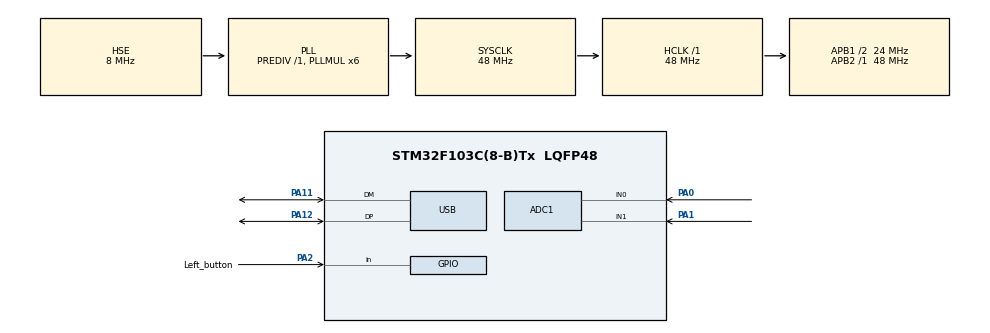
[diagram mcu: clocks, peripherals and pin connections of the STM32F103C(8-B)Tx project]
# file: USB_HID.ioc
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Mcu.Family=STM32F1
PA2.GPIO_PuPd=GPIO_PULLUP
USB_DEVICE.CLASS_NAME_FS=HID
Dma.ADC1.0.Instance=DMA1_Channel1
ADC1.Rank-0\#ChannelRegularConversion=1
PD1-OSC_OUT.Mode=HSE-External-Oscillator
ADC1.ContinuousConvMode=ENABLE
USB_DEVICE.VirtualModeFS=Hid_FS
PA11.Mode=Device
PD0-OSC_IN.Signal=RCC_OSC_IN
RCC.APB1CLKDivider=RCC_HCLK_DIV2
RCC.SYSCLKSource=RCC_SYSCLKSOURCE_PLLCLK
ProjectManager.StackSize=0x400
PA0-WKUP.Signal=ADCx_IN0
PD1-OSC_OUT.Signal=RCC_OSC_OUT
RCC.ADCPresc=RCC_ADCPCLK2_DIV4
PA13.Signal=SYS_JTMS-SWDIO
Dma.ADC1.0.PeriphDataAlignment=DMA_PDATAALIGN_HALFWORD
PA12.Signal=USB_DP
ProjectManager.TargetToolchain=MDK-ARM V5
Dma.ADC1.0.Mode=DMA_CIRCULAR
RCC.HCLKFreq_Value=48000000
Dma.ADC1.0.Priority=DMA_PRIORITY_LOW
RCC.APB2TimFreq_Value=48000000
ADC1.Channel-1\#ChannelRegularConversion=ADC_CHANNEL_1
Dma.ADC1.0.Direction=DMA_PERIPH_TO_MEMORY
RCC.USBFreq_Value=48000000
Dma.ADC1.0.MemDataAlignment=DMA_MDATAALIGN_HALFWORD
PA1.Signal=ADCx_IN1
RCC.AHBFreq_Value=48000000
PD0-OSC_IN.Mode=HSE-External-Oscillator
ADC1.Channel-0\#ChannelRegularConversion=ADC_CHANNEL_0
board=custom
RCC.PLLMUL=RCC_PLL_MUL6
VP_USB_DEVICE_VS_USB_DEVICE_HID_FS.Mode=HID_FS
RCC.APB2Freq_Value=48000000
PA14.Mode=Serial_Wire
Dma.ADC1.0.PeriphInc=DMA_PINC_DISABLE
NVIC.USB_LP_CAN1_RX0_IRQn=true\:0\:0\:false\:false\:true\:false\:true
SH.ADCx_IN0.0=ADC1_IN0,IN0
ADC1.NbrOfConversion=2
PA13.Mode=Serial_Wire
Mcu.Name=STM32F103C(8-B)Tx
ADC1.SamplingTime-0\#ChannelRegularConversion=ADC_SAMPLETIME_239CYCLES_5
PA2.Signal=GPIO_Input
ADC1.SamplingTime-1\#ChannelRegularConversion=ADC_SAMPLETIME_239CYCLES_5
RCC.SYSCLKFreq_VALUE=48000000
Mcu.Package=LQFP48
ADC1.master=1
PA12.Mode=Device
ADC1.Rank-1\#ChannelRegularConversion=2
PA2.GPIO_Label=Left_button
PA11.Signal=USB_DM
PA14.Signal=SYS_JTCK-SWCLK
Dma.ADC1.0.MemInc=DMA_MINC_ENABLE
ProjectManager.HeapSize=0x200
NVIC.PriorityGroup=NVIC_PRIORITYGROUP_4
ADC1.NbrOfConversionFlag=1
SH.ADCx_IN1.0=ADC1_IN1,IN1
RCC.APB1TimFreq_Value=48000000
NVIC.DMA1_Channel1_IRQn=true\:0\:0\:false\:false\:true\:false\:true
Dma.Request0=ADC1
RCC.APB1Freq_Value=24000000
USB_DEVICE.VirtualMode=Hid

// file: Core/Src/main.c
/* USER CODE BEGIN Header */
/**
  ******************************************************************************
  * @file           : main.c
  * @brief          : Main program body
  ******************************************************************************
  * @attention
  *
  * <h2><center>&copy; Copyright (c) 2021 STMicroelectronics.
  * All rights reserved.</center></h2>
  *
  * This software component is licensed by ST under Ultimate Liberty license
  * SLA0044, the "License"; You may not use this file except in compliance with
  * the License. You may obtain a copy of the License at:
  *                             www.st.com/SLA0044
  *
  ******************************************************************************
  */
/* USER CODE END Header */
#include "main.h"
#include "usb_device.h"

/* USER CODE BEGIN Includes */
#include "usbd_hid.h"
/* USER CODE END Includes */

/* USER CODE BEGIN PM */
int8_t mouse_report[5];
uint16_t ADC_val[2];
/* USER CODE END PM */

ADC_HandleTypeDef hadc1;
DMA_HandleTypeDef hdma_adc1;

void SystemClock_Config(void);
static void MX_GPIO_Init(void);
static void MX_DMA_Init(void);
static void MX_ADC1_Init(void);
/* USER CODE BEGIN PFP */
extern USBD_HandleTypeDef hUsbDeviceFS;
/* USER CODE END PFP */

/* USER CODE BEGIN 0 */
long map(long x, long in_min, long in_max, long out_min, long out_max) // chuyen doi gia tri min max
{
	long value;
  value = (x - in_min) * (out_max - out_min) / (in_max - in_min) + out_min;
	return value;
}
void Mouse_GetAction(void) // doc gia tri nut nhan vа toa do
{
	static uint8_t button = 0;
	int8_t XPos,YPos = 0;
	if(HAL_GPIO_ReadPin(Left_button_GPIO_Port,Left_button_Pin) == 0)
	{
		button = 1;
	}
	else
	{
		button = 0;
	}
	XPos = map(ADC_val[0],0,4008,-10,10); // chuyen doi
	YPos = map(ADC_val[1],0,3932,-10,10);

	mouse_report[0] = button; // cac nut nhan
	mouse_report[1] = XPos; // toa do
	mouse_report[2] = YPos;
	mouse_report[3] = 0;  //wheel
	mouse_report[4] = 0;  //wakeup

}
/* USER CODE END 0 */

int main(void)
{

  /* MCU Configuration--------------------------------------------------------*/

  /* Reset of all peripherals, Initializes the Flash interface and the Systick. */
  HAL_Init();

  /* Configure the system clock */
  SystemClock_Config();

  /* Initialize all configured peripherals */
  MX_GPIO_Init();
  MX_DMA_Init();
  MX_ADC1_Init();
  MX_USB_DEVICE_Init();
  /* USER CODE BEGIN 2 */
	HAL_ADC_Start_DMA(&hadc1,(uint32_t *)ADC_val,2);
  /* USER CODE END 2 */

  /* Infinite loop */
  while (1)
  {

    /* USER CODE BEGIN 3 */
		Mouse_GetAction();
		USBD_HID_SendReport(&hUsbDeviceFS, (uint8_t *)mouse_report,5);
  }
  /* USER CODE END 3 */
}

void SystemClock_Config(void)
{
  RCC_OscInitTypeDef RCC_OscInitStruct = {0};
  RCC_ClkInitTypeDef RCC_ClkInitStruct = {0};
  RCC_PeriphCLKInitTypeDef PeriphClkInit = {0};

  /** Initializes the RCC Oscillators according to the specified parameters
  * in the RCC_OscInitTypeDef structure.
  */
  RCC_OscInitStruct.OscillatorType = RCC_OSCILLATORTYPE_HSE;
  RCC_OscInitStruct.HSEState = RCC_HSE_ON;
  RCC_OscInitStruct.HSEPredivValue = RCC_HSE_PREDIV_DIV1;
  RCC_OscInitStruct.HSIState = RCC_HSI_ON;
  RCC_OscInitStruct.PLL.PLLState = RCC_PLL_ON;
  RCC_OscInitStruct.PLL.PLLSource = RCC_PLLSOURCE_HSE;
  RCC_OscInitStruct.PLL.PLLMUL = RCC_PLL_MUL6;
  if (HAL_RCC_OscConfig(&RCC_OscInitStruct) != HAL_OK)
  {
    Error_Handler();
  }
  /** Initializes the CPU, AHB and APB buses clocks
  */
  RCC_ClkInitStruct.ClockType = RCC_CLOCKTYPE_HCLK|RCC_CLOCKTYPE_SYSCLK
                              |RCC_CLOCKTYPE_PCLK1|RCC_CLOCKTYPE_PCLK2;
  RCC_ClkInitStruct.SYSCLKSource = RCC_SYSCLKSOURCE_PLLCLK;
  RCC_ClkInitStruct.AHBCLKDivider = RCC_SYSCLK_DIV1;
  RCC_ClkInitStruct.APB1CLKDivider = RCC_HCLK_DIV2;
  RCC_ClkInitStruct.APB2CLKDivider = RCC_HCLK_DIV1;

  if (HAL_RCC_ClockConfig(&RCC_ClkInitStruct, FLASH_LATENCY_1) != HAL_OK)
  {
    Error_Handler();
  }
  PeriphClkInit.PeriphClockSelection = RCC_PERIPHCLK_ADC|RCC_PERIPHCLK_USB;
  PeriphClkInit.AdcClockSelection = RCC_ADCPCLK2_DIV4;
  PeriphClkInit.UsbClockSelection = RCC_USBCLKSOURCE_PLL;
  if (HAL_RCCEx_PeriphCLKConfig(&PeriphClkInit) != HAL_OK)
  {
    Error_Handler();
  }
}

static void MX_ADC1_Init(void)
{

  ADC_ChannelConfTypeDef sConfig = {0};

  /** Common config
  */
  hadc1.Instance = ADC1;
  hadc1.Init.ScanConvMode = ADC_SCAN_ENABLE;
  hadc1.Init.ContinuousConvMode = ENABLE;
  hadc1.Init.DiscontinuousConvMode = DISABLE;
  hadc1.Init.ExternalTrigConv = ADC_SOFTWARE_START;
  hadc1.Init.DataAlign = ADC_DATAALIGN_RIGHT;
  hadc1.Init.NbrOfConversion = 2;
  if (HAL_ADC_Init(&hadc1) != HAL_OK)
  {
    Error_Handler();
  }
  /** Configure Regular Channel
  */
  sConfig.Channel = ADC_CHANNEL_0;
  sConfig.Rank = ADC_REGULAR_RANK_1;
  sConfig.SamplingTime = ADC_SAMPLETIME_239CYCLES_5;
  if (HAL_ADC_ConfigChannel(&hadc1, &sConfig) != HAL_OK)
  {
    Error_Handler();
  }
  /** Configure Regular Channel
  */
  sConfig.Channel = ADC_CHANNEL_1;
  sConfig.Rank = ADC_REGULAR_RANK_2;
  if (HAL_ADC_ConfigChannel(&hadc1, &sConfig) != HAL_OK)
  {
    Error_Handler();
  }

}

static void MX_DMA_Init(void)
{

  /* DMA controller clock enable */
  __HAL_RCC_DMA1_CLK_ENABLE();

  /* DMA interrupt init */
  /* DMA1_Channel1_IRQn interrupt configuration */
  HAL_NVIC_SetPriority(DMA1_Channel1_IRQn, 0, 0);
  HAL_NVIC_EnableIRQ(DMA1_Channel1_IRQn);

}

static void MX_GPIO_Init(void)
{
  GPIO_InitTypeDef GPIO_InitStruct = {0};

  /* GPIO Ports Clock Enable */
  __HAL_RCC_GPIOC_CLK_ENABLE();
  __HAL_RCC_GPIOD_CLK_ENABLE();
  __HAL_RCC_GPIOA_CLK_ENABLE();

  /*Configure GPIO pin Output Level */
  HAL_GPIO_WritePin(LED_GPIO_Port, LED_Pin, GPIO_PIN_RESET);

  /*Configure GPIO pin : LED_Pin */
  GPIO_InitStruct.Pin = LED_Pin;
  GPIO_InitStruct.Mode = GPIO_MODE_OUTPUT_PP;
  GPIO_InitStruct.Pull = GPIO_NOPULL;
  GPIO_InitStruct.Speed = GPIO_SPEED_FREQ_LOW;
  HAL_GPIO_Init(LED_GPIO_Port, &GPIO_InitStruct);

  /*Configure GPIO pin : Left_button_Pin */
  GPIO_InitStruct.Pin = Left_button_Pin;
  GPIO_InitStruct.Mode = GPIO_MODE_INPUT;
  GPIO_InitStruct.Pull = GPIO_PULLUP;
  HAL_GPIO_Init(Left_button_GPIO_Port, &GPIO_InitStruct);

}

void Error_Handler(void)
{
}

/************************ (C) COPYRIGHT STMicroelectronics *****END OF FILE****/
